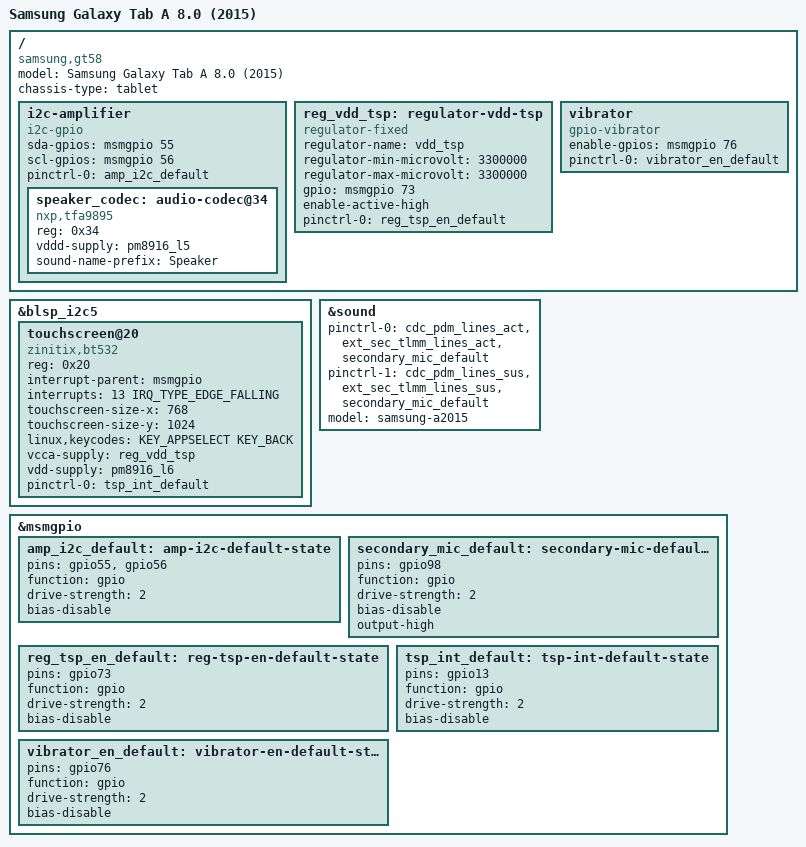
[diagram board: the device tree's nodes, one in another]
// SPDX-License-Identifier: GPL-2.0-only

/dts-v1/;

#include "msm8916-samsung-gt5-common.dtsi"

/ {
	model = "Samsung Galaxy Tab A 8.0 (2015)";
	compatible = "samsung,gt58", "qcom,msm8916";
	chassis-type = "tablet";

	i2c-amplifier {
		compatible = "i2c-gpio";
		sda-gpios = <&msmgpio 55 (GPIO_ACTIVE_HIGH|GPIO_OPEN_DRAIN)>;
		scl-gpios = <&msmgpio 56 (GPIO_ACTIVE_HIGH|GPIO_OPEN_DRAIN)>;

		pinctrl-0 = <&amp_i2c_default>;
		pinctrl-names = "default";

		#address-cells = <1>;
		#size-cells = <0>;

		speaker_codec: audio-codec@34 {
			compatible = "nxp,tfa9895";
			reg = <0x34>;
			vddd-supply = <&pm8916_l5>;
			sound-name-prefix = "Speaker";
			#sound-dai-cells = <0>;
		};
	};

	reg_vdd_tsp: regulator-vdd-tsp {
		compatible = "regulator-fixed";
		regulator-name = "vdd_tsp";
		regulator-min-microvolt = <3300000>;
		regulator-max-microvolt = <3300000>;

		gpio = <&msmgpio 73 GPIO_ACTIVE_HIGH>;
		enable-active-high;

		pinctrl-0 = <&reg_tsp_en_default>;
		pinctrl-names = "default";
	};

	vibrator {
		compatible = "gpio-vibrator";
		enable-gpios = <&msmgpio 76 GPIO_ACTIVE_HIGH>;

		pinctrl-0 = <&vibrator_en_default>;
		pinctrl-names = "default";
	};
};

&blsp_i2c5 {
	status = "okay";

	touchscreen@20 {
		compatible = "zinitix,bt532";
		reg = <0x20>;
		interrupt-parent = <&msmgpio>;
		interrupts = <13 IRQ_TYPE_EDGE_FALLING>;

		touchscreen-size-x = <768>;
		touchscreen-size-y = <1024>;
		linux,keycodes = <KEY_APPSELECT KEY_BACK>;

		vcca-supply = <&reg_vdd_tsp>;
		vdd-supply = <&pm8916_l6>;

		pinctrl-0 = <&tsp_int_default>;
		pinctrl-names = "default";
	};
};

&sound {
	/* FIXME: Avoid powering secondary mic permanently */
	pinctrl-0 = <&cdc_pdm_lines_act &ext_sec_tlmm_lines_act &secondary_mic_default>;
	pinctrl-1 = <&cdc_pdm_lines_sus &ext_sec_tlmm_lines_sus &secondary_mic_default>;
	pinctrl-names = "default", "sleep";

	model = "samsung-a2015";
};

&msmgpio {
	amp_i2c_default: amp-i2c-default-state {
		pins = "gpio55", "gpio56";
		function = "gpio";
		drive-strength = <2>;
		bias-disable;
	};

	secondary_mic_default: secondary-mic-default-state {
		pins = "gpio98";
		function = "gpio";
		drive-strength = <2>;
		bias-disable;
		output-high;
	};

	reg_tsp_en_default: reg-tsp-en-default-state {
		pins = "gpio73";
		function = "gpio";
		drive-strength = <2>;
		bias-disable;
	};

	tsp_int_default: tsp-int-default-state {
		pins = "gpio13";
		function = "gpio";
		drive-strength = <2>;
		bias-disable;
	};

	vibrator_en_default: vibrator-en-default-state {
		pins = "gpio76";
		function = "gpio";
		drive-strength = <2>;
		bias-disable;
	};
};
